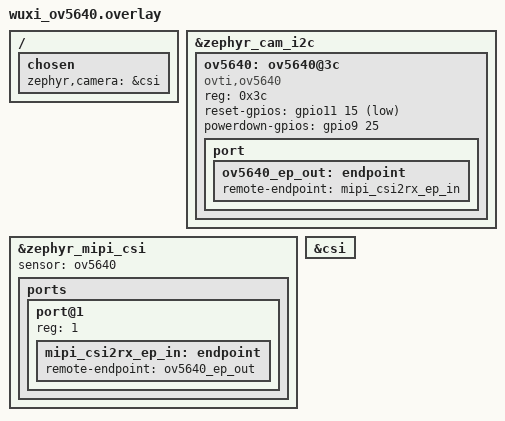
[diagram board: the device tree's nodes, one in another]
/*
 * Copyright 2024 NXP
 *
 * SPDX-License-Identifier: Apache-2.0
 */

/{
	chosen {
		zephyr,camera = &csi;
	};
};

&zephyr_cam_i2c {
    status = "okay";

    ov5640: ov5640@3c {
        compatible = "ovti,ov5640";
        reg = <0x3c>;
        reset-gpios = <&gpio11 15 GPIO_ACTIVE_LOW>;
        powerdown-gpios = <&gpio9 25 GPIO_ACTIVE_HIGH>;

        port {
            ov5640_ep_out: endpoint {
                remote-endpoint = <&mipi_csi2rx_ep_in>;
            };
        };
    };
};

&zephyr_mipi_csi {
    status = "okay";
    sensor = <&ov5640>;

    ports {
        port@1 {
            reg = <1>;

            mipi_csi2rx_ep_in: endpoint {
                remote-endpoint = <&ov5640_ep_out>;
            };
        };
    };
};

&csi {
    status = "okay";
};
